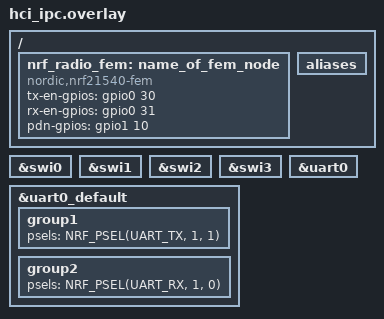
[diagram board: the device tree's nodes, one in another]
// To get started, press Ctrl+Space to bring up the completion menu and view the available nodes.

// You can also use the buttons in the sidebar to perform actions on nodes.
// Actions currently available include:

// * Enabling / disabling the node
// * Adding the bus to a bus
// * Removing the node
// * Connecting ADC channels

// For more help, browse the DeviceTree documentation at https://docs.zephyrproject.org/latest/guides/dts/index.html
// You can also visit the nRF DeviceTree extension documentation at https://nrfconnect.github.io/vscode-nrf-connect/devicetree/nrfdevicetree.html
// https://developer.nordicsemi.com/nRF_Connect_SDK/doc/latest/nrf/device_guides/working_with_fem.html#ug-radio-fem-nrf21540-spi-gpio
/ {
    nrf_radio_fem: name_of_fem_node {
       compatible  = "nordic,nrf21540-fem";
       tx-en-gpios = <&gpio0 30 GPIO_ACTIVE_HIGH>;
       rx-en-gpios = <&gpio0 31 GPIO_ACTIVE_HIGH>;
       pdn-gpios   = <&gpio1 10 GPIO_ACTIVE_HIGH>;
 };

    aliases {
        /delete-property/ sw2;
        /delete-property/ sw3;
    };
};

&swi0 {
    /delete-property/ status;
};

&swi1 {
    /delete-property/ status;
};

&swi2 {
    /delete-property/ status;
};

&swi3 {
    /delete-property/ status;
};

&uart0 {
    /delete-property/ status;
};
/delete-node/ &button2;
/delete-node/ &button3;

&uart0_default {
    group1 {
        psels = <NRF_PSEL(UART_TX, 1, 1)>;
    };

    group2 {
        psels = <NRF_PSEL(UART_RX, 1, 0)>;
    };
};
